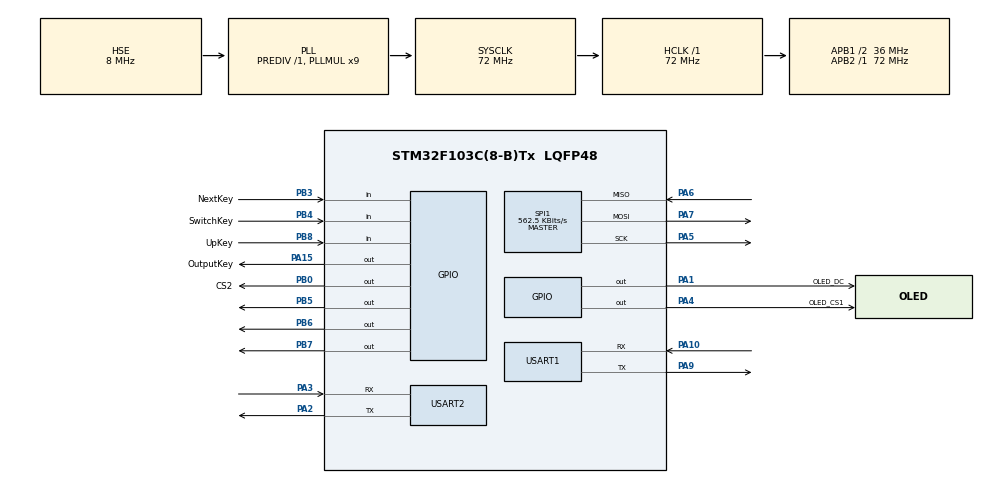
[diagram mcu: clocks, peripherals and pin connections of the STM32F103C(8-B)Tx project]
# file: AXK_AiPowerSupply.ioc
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Dma.Request0=USART1_RX
Dma.Request1=USART1_TX
Dma.USART1_RX.0.Direction=DMA_PERIPH_TO_MEMORY
Dma.USART1_RX.0.Instance=DMA1_Channel5
Dma.USART1_RX.0.MemDataAlignment=DMA_MDATAALIGN_BYTE
Dma.USART1_RX.0.MemInc=DMA_MINC_ENABLE
Dma.USART1_RX.0.Mode=DMA_NORMAL
Dma.USART1_RX.0.PeriphDataAlignment=DMA_PDATAALIGN_BYTE
Dma.USART1_RX.0.PeriphInc=DMA_PINC_DISABLE
Dma.USART1_RX.0.Priority=DMA_PRIORITY_LOW
Dma.USART1_TX.1.Direction=DMA_MEMORY_TO_PERIPH
Dma.USART1_TX.1.Instance=DMA1_Channel4
Dma.USART1_TX.1.MemDataAlignment=DMA_MDATAALIGN_BYTE
Dma.USART1_TX.1.MemInc=DMA_MINC_ENABLE
Dma.USART1_TX.1.Mode=DMA_NORMAL
Dma.USART1_TX.1.PeriphDataAlignment=DMA_PDATAALIGN_BYTE
Dma.USART1_TX.1.PeriphInc=DMA_PINC_DISABLE
Dma.USART1_TX.1.Priority=DMA_PRIORITY_LOW
FREERTOS.BinarySemaphores01=uart1TxDoneSem,Dynamic,NULL,Depleted
FREERTOS.Mutexes01=uart1TxMutex,Dynamic,NULL,Available
FREERTOS.Queues01=BtnQueue,16,uint8_t,0,Dynamic,NULL,NULL
FREERTOS.Tasks01=defaultTask,24,384,StartDefaultTask,Default,NULL,Dynamic,NULL,NULL;KeyTask,8,512,StartKeyTask,Default,NULL,Dynamic,NULL,NULL
FREERTOS.configTOTAL_HEAP_SIZE=6144
Mcu.Family=STM32F1
Mcu.Name=STM32F103C(8-B)Tx
Mcu.Package=LQFP48
NVIC.DMA1_Channel4_IRQn=true\:5\:0\:false\:false\:true\:true\:false\:true\:true
NVIC.DMA1_Channel5_IRQn=true\:5\:0\:false\:false\:true\:true\:false\:true\:true
NVIC.PriorityGroup=NVIC_PRIORITYGROUP_4
NVIC.TIM4_IRQn=true\:15\:0\:false\:false\:true\:false\:false\:true\:true
NVIC.TimeBase=TIM4_IRQn
NVIC.TimeBaseIP=TIM4
NVIC.USART1_IRQn=true\:5\:0\:false\:false\:true\:true\:true\:true\:true
NVIC.USART2_IRQn=true\:5\:0\:false\:false\:true\:true\:true\:true\:true
PA1.GPIO_Label=OLED_DC
PA1.PinState=GPIO_PIN_SET
PA1.Signal=GPIO_Output
PA10.Mode=Asynchronous
PA10.Signal=USART1_RX
PA13.Mode=Serial_Wire
PA13.Signal=SYS_JTMS-SWDIO
PA14.Mode=Serial_Wire
PA14.Signal=SYS_JTCK-SWCLK
PA15.GPIO_Label=OutputKey
PA15.GPIO_PuPd=GPIO_PULLDOWN
PA15.Signal=GPIO_Output
PA2.Mode=Asynchronous
PA2.Signal=USART2_TX
PA3.Mode=Asynchronous
PA3.Signal=USART2_RX
PA4.GPIO_Label=OLED_CS1
PA4.PinState=GPIO_PIN_SET
PA4.Signal=GPIO_Output
PA5.Mode=Full_Duplex_Master
PA5.Signal=SPI1_SCK
PA6.Mode=Full_Duplex_Master
PA6.Signal=SPI1_MISO
PA7.Mode=Full_Duplex_Master
PA7.Signal=SPI1_MOSI
PA9.Mode=Asynchronous
PA9.Signal=USART1_TX
PB0.GPIO_Label=CS2
PB0.PinState=GPIO_PIN_SET
PB0.Signal=GPIO_Output
PB3.GPIO_Label=NextKey
PB3.GPIO_PuPd=GPIO_PULLUP
PB3.Signal=GPIO_Input
PB4.GPIO_Label=SwitchKey
PB4.GPIO_PuPd=GPIO_PULLUP
PB4.Signal=GPIO_Input
PB5.Signal=GPIO_Output
PB6.Signal=GPIO_Output
PB7.Signal=GPIO_Output
PB8.GPIO_Label=UpKey
PB8.GPIO_Mode=GPIO_MODE_INPUT
PB8.GPIO_PuPd=GPIO_PULLUP
PB8.Signal=GPIO_Input
PD0-OSC_IN.Mode=HSE-External-Oscillator
PD0-OSC_IN.Signal=RCC_OSC_IN
PD1-OSC_OUT.Mode=HSE-External-Oscillator
PD1-OSC_OUT.Signal=RCC_OSC_OUT
ProjectManager.HeapSize=0x200
ProjectManager.StackSize=0x400
ProjectManager.TargetToolchain=CMake
RCC.AHBFreq_Value=72000000
RCC.APB1CLKDivider=RCC_HCLK_DIV2
RCC.APB1Freq_Value=36000000
RCC.APB1TimFreq_Value=72000000
RCC.APB2Freq_Value=72000000
RCC.APB2TimCLKDivider=1
RCC.APB2TimFreq_Value=72000000
RCC.HCLKFreq_Value=72000000
RCC.PLLMUL=RCC_PLL_MUL9
RCC.PLLSourceVirtual=RCC_PLLSOURCE_HSE
RCC.SYSCLKFreq_VALUE=72000000
RCC.SYSCLKSource=RCC_SYSCLKSOURCE_PLLCLK
RCC.USBFreq_Value=72000000
SPI1.BaudRatePrescaler=SPI_BAUDRATEPRESCALER_128
SPI1.CalculateBaudRate=562.5 KBits/s
SPI1.Direction=SPI_DIRECTION_2LINES
SPI1.Mode=SPI_MODE_MASTER
SPI1.VirtualType=VM_MASTER
USART1.VirtualMode=VM_ASYNC
USART2.VirtualMode=VM_ASYNC
VP_FREERTOS_VS_CMSIS_V2.Mode=CMSIS_V2
VP_SYS_VS_tim4.Mode=TIM4
board=custom

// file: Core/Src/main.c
/* USER CODE BEGIN Header */
/**
  ******************************************************************************
  * @file           : main.c
  * @brief          : Main program body
  ******************************************************************************
  * @attention
  *
  * Copyright (c) 2026 STMicroelectronics.
  * All rights reserved.
  *
  * This software is licensed under terms that can be found in the LICENSE file
  * in the root directory of this software component.
  * If no LICENSE file comes with this software, it is provided AS-IS.
  *
  ******************************************************************************
  */
/* USER CODE END Header */
#include "main.h"
#include "cmsis_os.h"
#include "dma.h"
#include "spi.h"
#include "usart.h"
#include "gpio.h"

void SystemClock_Config(void);
void MX_FREERTOS_Init(void);

int main(void)
{

  /* MCU Configuration--------------------------------------------------------*/

  /* Reset of all peripherals, Initializes the Flash interface and the Systick. */
  HAL_Init();

  /* Configure the system clock */
  SystemClock_Config();

  /* Initialize all configured peripherals */
  MX_GPIO_Init();
  MX_DMA_Init();
  MX_USART1_UART_Init();
  MX_SPI1_Init();
  MX_USART2_UART_Init();

  /* Init scheduler */
  osKernelInitialize();  /* Call init function for freertos objects (in cmsis_os2.c) */
  MX_FREERTOS_Init();

  /* Start scheduler */
  osKernelStart();

  /* We should never get here as control is now taken by the scheduler */

  /* Infinite loop */
  while (1)
  {

  }
}

void SystemClock_Config(void)
{
  RCC_OscInitTypeDef RCC_OscInitStruct = {0};
  RCC_ClkInitTypeDef RCC_ClkInitStruct = {0};

  /** Initializes the RCC Oscillators according to the specified parameters
  * in the RCC_OscInitTypeDef structure.
  */
  RCC_OscInitStruct.OscillatorType = RCC_OSCILLATORTYPE_HSE;
  RCC_OscInitStruct.HSEState = RCC_HSE_ON;
  RCC_OscInitStruct.HSEPredivValue = RCC_HSE_PREDIV_DIV1;
  RCC_OscInitStruct.HSIState = RCC_HSI_ON;
  RCC_OscInitStruct.PLL.PLLState = RCC_PLL_ON;
  RCC_OscInitStruct.PLL.PLLSource = RCC_PLLSOURCE_HSE;
  RCC_OscInitStruct.PLL.PLLMUL = RCC_PLL_MUL9;
  if (HAL_RCC_OscConfig(&RCC_OscInitStruct) != HAL_OK)
  {
    Error_Handler();
  }

  /** Initializes the CPU, AHB and APB buses clocks
  */
  RCC_ClkInitStruct.ClockType = RCC_CLOCKTYPE_HCLK|RCC_CLOCKTYPE_SYSCLK
                              |RCC_CLOCKTYPE_PCLK1|RCC_CLOCKTYPE_PCLK2;
  RCC_ClkInitStruct.SYSCLKSource = RCC_SYSCLKSOURCE_PLLCLK;
  RCC_ClkInitStruct.AHBCLKDivider = RCC_SYSCLK_DIV1;
  RCC_ClkInitStruct.APB1CLKDivider = RCC_HCLK_DIV2;
  RCC_ClkInitStruct.APB2CLKDivider = RCC_HCLK_DIV1;

  if (HAL_RCC_ClockConfig(&RCC_ClkInitStruct, FLASH_LATENCY_2) != HAL_OK)
  {
    Error_Handler();
  }
}

void HAL_TIM_PeriodElapsedCallback(TIM_HandleTypeDef *htim)
{
  if (htim->Instance == TIM4)
  {
    HAL_IncTick();
  }
}

void Error_Handler(void)
{
  __disable_irq();
  while (1)
  {
  }
}

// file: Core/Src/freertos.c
/* USER CODE BEGIN Header */
/**
  ******************************************************************************
  * File Name          : freertos.c
  * Description        : Code for freertos applications
  ******************************************************************************
  * @attention
  *
  * Copyright (c) 2026 STMicroelectronics.
  * All rights reserved.
  *
  * This software is licensed under terms that can be found in the LICENSE file
  * in the root directory of this software component.
  * If no LICENSE file comes with this software, it is provided AS-IS.
  *
  ******************************************************************************
  */
/* USER CODE END Header */

#include "FreeRTOS.h"
#include "task.h"
#include "main.h"
#include "cmsis_os.h"

/* USER CODE BEGIN Includes */
#include "axk_app.h"
/* USER CODE END Includes */

/* USER CODE BEGIN PM */

// 不定长数据接收完成回调函数

/* USER CODE END PM */

/* Definitions for defaultTask */
osThreadId_t defaultTaskHandle;
const osThreadAttr_t defaultTask_attributes = {
  .name = "defaultTask",
  .stack_size = 384 * 4,
  .priority = (osPriority_t) osPriorityNormal,
};
/* Definitions for KeyTask */
osThreadId_t KeyTaskHandle;
const osThreadAttr_t KeyTask_attributes = {
  .name = "KeyTask",
  .stack_size = 512 * 4,
  .priority = (osPriority_t) osPriorityLow,
};
/* Definitions for BtnQueue */
osMessageQueueId_t BtnQueueHandle;
const osMessageQueueAttr_t BtnQueue_attributes = {
  .name = "BtnQueue"
};
/* Definitions for uart1TxMutex */
osMutexId_t uart1TxMutexHandle;
const osMutexAttr_t uart1TxMutex_attributes = {
  .name = "uart1TxMutex"
};
/* Definitions for uart1TxDoneSem */
osSemaphoreId_t uart1TxDoneSemHandle;
const osSemaphoreAttr_t uart1TxDoneSem_attributes = {
  .name = "uart1TxDoneSem"
};

void StartDefaultTask(void *argument);
void StartKeyTask(void *argument);

void MX_FREERTOS_Init(void); /* (MISRA C 2004 rule 8.1) */

void MX_FREERTOS_Init(void) {
  /* Create the mutex(es) */
  /* creation of uart1TxMutex */
  uart1TxMutexHandle = osMutexNew(&uart1TxMutex_attributes);

  /* Create the semaphores(s) */
  /* creation of uart1TxDoneSem */
  uart1TxDoneSemHandle = osSemaphoreNew(1, 0, &uart1TxDoneSem_attributes);

  /* Create the queue(s) */
  /* creation of BtnQueue */
  BtnQueueHandle = osMessageQueueNew (16, sizeof(uint8_t), &BtnQueue_attributes);

  /* Create the thread(s) */
  /* creation of defaultTask */
  defaultTaskHandle = osThreadNew(StartDefaultTask, NULL, &defaultTask_attributes);

  /* creation of KeyTask */
  KeyTaskHandle = osThreadNew(StartKeyTask, NULL, &KeyTask_attributes);

}

void StartDefaultTask(void *argument)
{
  /* USER CODE BEGIN StartDefaultTask */
  axk_app_default_task();
  /* USER CODE END StartDefaultTask */
}

void StartKeyTask(void *argument)
{
  /* USER CODE BEGIN StartKeyTask */
  axk_app_key_task();
  /* USER CODE END StartKeyTask */
}

/* USER CODE BEGIN Application */
void HAL_UARTEx_RxEventCallback(UART_HandleTypeDef *huart, uint16_t Size)
{
    axk_app_uart_rx_callback(huart, Size);
}
/* USER CODE END Application */
